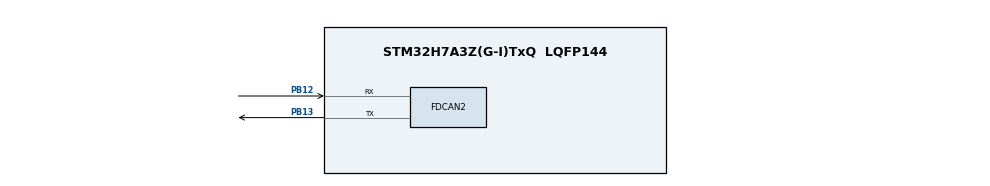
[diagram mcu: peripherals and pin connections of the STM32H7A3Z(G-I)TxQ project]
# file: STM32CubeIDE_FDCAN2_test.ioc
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FDCAN2.AutoRetransmission=ENABLE
FDCAN2.DataPrescaler=25
FDCAN2.DataTimeSeg1=2
FDCAN2.FrameFormat=FDCAN_FRAME_FD_NO_BRS
FDCAN2.MessageRAMOffset=11
FDCAN2.NominalSyncJumpWidth=13
FDCAN2.NominalTimeSeg1=86
FDCAN2.NominalTimeSeg2=13
FDCAN2.RxFifo1ElmtSize=FDCAN_DATA_BYTES_12
FDCAN2.RxFifo1ElmtsNbr=1
FDCAN2.TxElmtSize=FDCAN_DATA_BYTES_12
FDCAN2.TxFifoQueueElmtsNbr=1
Mcu.Family=STM32H7
Mcu.Name=STM32H7A3Z(G-I)TxQ
Mcu.Package=LQFP144
NVIC.FDCAN2_IT0_IRQn=true\:0\:0\:false\:false\:true\:true\:true
NVIC.PriorityGroup=NVIC_PRIORITYGROUP_4
PB12.Mode=FDCAN_Activate
PB12.Signal=FDCAN2_RX
PB13.Mode=FDCAN_Activate
PB13.Signal=FDCAN2_TX
ProjectManager.HeapSize=0x200
ProjectManager.StackSize=0x400
ProjectManager.TargetToolchain=STM32CubeIDE
RCC.ADCFreq_Value=129000000
RCC.APB1Freq_Value=32000000
RCC.APB2Freq_Value=32000000
RCC.APB3Freq_Value=32000000
RCC.APB4Freq_Value=32000000
RCC.CDPPRE=RCC_APB3_DIV2
RCC.CDPPRE1=RCC_APB1_DIV2
RCC.CDPPRE2=RCC_APB2_DIV2
RCC.CortexFreq_Value=64000000
RCC.DIVM1=4
RCC.DIVN1=8
RCC.DIVQ1=1
RCC.HCLKFreq_Value=64000000
RCC.PLLFRACN=0
RCC.SRDPPRE=RCC_APB4_DIV2
RCC.SYSCLKFreq_VALUE=64000000
RCC.USBFreq_Value=128000000
board=custom

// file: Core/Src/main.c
/* USER CODE BEGIN Header */
/**
  ******************************************************************************
  * @file           : main.c
  * @brief          : Main program body
  ******************************************************************************
  * @attention
  *
  * Copyright (c) 2023 STMicroelectronics.
  * All rights reserved.
  *
  * This software is licensed under terms that can be found in the LICENSE file
  * in the root directory of this software component.
  * If no LICENSE file comes with this software, it is provided AS-IS.
  *
  ******************************************************************************
  */
/* USER CODE END Header */
#include "main.h"

/* USER CODE BEGIN Includes */
#include <stdio.h>
/* USER CODE END Includes */

FDCAN_HandleTypeDef hfdcan2;

void SystemClock_Config(void);
static void MX_GPIO_Init(void);
static void MX_FDCAN2_Init(void);

/* USER CODE BEGIN 0 */

int indx = 0;
// FDCAN2 Defines
FDCAN_TxHeaderTypeDef   TxHeader2;
FDCAN_RxHeaderTypeDef   RxHeader2;
uint8_t               TxData2[12];
uint8_t               RxData2[12];

// FDCAN2 Callback
void HAL_FDCAN_RxFifo1Callback(FDCAN_HandleTypeDef *hfdcan, uint32_t RxFifo1ITs)
{
  if((RxFifo1ITs & FDCAN_IT_RX_FIFO1_NEW_MESSAGE) != RESET)
  {
    /* Retreive Rx messages from RX FIFO0 */
    if (HAL_FDCAN_GetRxMessage(hfdcan, FDCAN_RX_FIFO1, &RxHeader2, RxData2) != HAL_OK)
    {
    /* Reception Error */
    Error_Handler();
    }

    if (HAL_FDCAN_ActivateNotification(hfdcan, FDCAN_IT_RX_FIFO1_NEW_MESSAGE, 0) != HAL_OK)
    {
      /* Notification Error */
      Error_Handler();
    }

	  sprintf ((char *)TxData2, "FDCAN2TX %d", indx++);

	  if (HAL_FDCAN_AddMessageToTxFifoQ(&hfdcan2, &TxHeader2, TxData2)!= HAL_OK)
	  {
		  Error_Handler();
	  }
  }
}
/* USER CODE END 0 */

int main(void)
{

  /* MCU Configuration--------------------------------------------------------*/

  /* Reset of all peripherals, Initializes the Flash interface and the Systick. */
  HAL_Init();

  /* Configure the system clock */
  SystemClock_Config();

  /* Initialize all configured peripherals */
  MX_GPIO_Init();
  MX_FDCAN2_Init();
  /* USER CODE BEGIN 2 */

  // STart FDCAN2
   if(HAL_FDCAN_Start(&hfdcan2)!= HAL_OK)
   {
    Error_Handler();
   }
   // Activate the notification for new data in FIFO1 for FDCAN2
     if (HAL_FDCAN_ActivateNotification(&hfdcan2, FDCAN_IT_RX_FIFO1_NEW_MESSAGE, 0) != HAL_OK)
     {
       /* Notification Error */
       Error_Handler();
     }
     // Configure TX Header for FDCAN2
       TxHeader2.Identifier = 0x22;
       TxHeader2.IdType = FDCAN_STANDARD_ID;
       TxHeader2.TxFrameType = FDCAN_DATA_FRAME;
       TxHeader2.DataLength = FDCAN_DLC_BYTES_12;
       TxHeader2.ErrorStateIndicator = FDCAN_ESI_ACTIVE;
       TxHeader2.BitRateSwitch = FDCAN_BRS_OFF;
       TxHeader2.FDFormat = FDCAN_FD_CAN;
       TxHeader2.TxEventFifoControl = FDCAN_NO_TX_EVENTS;
       TxHeader2.MessageMarker = 0;

  /* USER CODE END 2 */

  /* Infinite loop */
  while (1)
  {

  }
}

void SystemClock_Config(void)
{
  RCC_OscInitTypeDef RCC_OscInitStruct = {0};
  RCC_ClkInitTypeDef RCC_ClkInitStruct = {0};

  /** Supply configuration update enable
  */
  HAL_PWREx_ConfigSupply(PWR_DIRECT_SMPS_SUPPLY);
  /** Configure the main internal regulator output voltage
  */
  __HAL_PWR_VOLTAGESCALING_CONFIG(PWR_REGULATOR_VOLTAGE_SCALE3);

  while(!__HAL_PWR_GET_FLAG(PWR_FLAG_VOSRDY)) {}
  /** Initializes the RCC Oscillators according to the specified parameters
  * in the RCC_OscInitTypeDef structure.
  */
  RCC_OscInitStruct.OscillatorType = RCC_OSCILLATORTYPE_HSI;
  RCC_OscInitStruct.HSIState = RCC_HSI_DIV1;
  RCC_OscInitStruct.HSICalibrationValue = RCC_HSICALIBRATION_DEFAULT;
  RCC_OscInitStruct.PLL.PLLState = RCC_PLL_ON;
  RCC_OscInitStruct.PLL.PLLSource = RCC_PLLSOURCE_HSI;
  RCC_OscInitStruct.PLL.PLLM = 4;
  RCC_OscInitStruct.PLL.PLLN = 8;
  RCC_OscInitStruct.PLL.PLLP = 2;
  RCC_OscInitStruct.PLL.PLLQ = 1;
  RCC_OscInitStruct.PLL.PLLR = 2;
  RCC_OscInitStruct.PLL.PLLRGE = RCC_PLL1VCIRANGE_3;
  RCC_OscInitStruct.PLL.PLLVCOSEL = RCC_PLL1VCOWIDE;
  RCC_OscInitStruct.PLL.PLLFRACN = 0;
  if (HAL_RCC_OscConfig(&RCC_OscInitStruct) != HAL_OK)
  {
    Error_Handler();
  }
  /** Initializes the CPU, AHB and APB buses clocks
  */
  RCC_ClkInitStruct.ClockType = RCC_CLOCKTYPE_HCLK|RCC_CLOCKTYPE_SYSCLK
                              |RCC_CLOCKTYPE_PCLK1|RCC_CLOCKTYPE_PCLK2
                              |RCC_CLOCKTYPE_D3PCLK1|RCC_CLOCKTYPE_D1PCLK1;
  RCC_ClkInitStruct.SYSCLKSource = RCC_SYSCLKSOURCE_HSI;
  RCC_ClkInitStruct.SYSCLKDivider = RCC_SYSCLK_DIV1;
  RCC_ClkInitStruct.AHBCLKDivider = RCC_HCLK_DIV1;
  RCC_ClkInitStruct.APB3CLKDivider = RCC_APB3_DIV2;
  RCC_ClkInitStruct.APB1CLKDivider = RCC_APB1_DIV2;
  RCC_ClkInitStruct.APB2CLKDivider = RCC_APB2_DIV2;
  RCC_ClkInitStruct.APB4CLKDivider = RCC_APB4_DIV2;

  if (HAL_RCC_ClockConfig(&RCC_ClkInitStruct, FLASH_LATENCY_2) != HAL_OK)
  {
    Error_Handler();
  }
}

static void MX_FDCAN2_Init(void)
{

  hfdcan2.Instance = FDCAN2;
  hfdcan2.Init.FrameFormat = FDCAN_FRAME_FD_NO_BRS;
  hfdcan2.Init.Mode = FDCAN_MODE_NORMAL;
  hfdcan2.Init.AutoRetransmission = ENABLE;
  hfdcan2.Init.TransmitPause = DISABLE;
  hfdcan2.Init.ProtocolException = DISABLE;
  hfdcan2.Init.NominalPrescaler = 1;
  hfdcan2.Init.NominalSyncJumpWidth = 13;
  hfdcan2.Init.NominalTimeSeg1 = 86;
  hfdcan2.Init.NominalTimeSeg2 = 13;
  hfdcan2.Init.DataPrescaler = 25;
  hfdcan2.Init.DataSyncJumpWidth = 1;
  hfdcan2.Init.DataTimeSeg1 = 2;
  hfdcan2.Init.DataTimeSeg2 = 1;
  hfdcan2.Init.MessageRAMOffset = 11;
  hfdcan2.Init.StdFiltersNbr = 0;
  hfdcan2.Init.ExtFiltersNbr = 0;
  hfdcan2.Init.RxFifo0ElmtsNbr = 0;
  hfdcan2.Init.RxFifo0ElmtSize = FDCAN_DATA_BYTES_8;
  hfdcan2.Init.RxFifo1ElmtsNbr = 1;
  hfdcan2.Init.RxFifo1ElmtSize = FDCAN_DATA_BYTES_12;
  hfdcan2.Init.RxBuffersNbr = 0;
  hfdcan2.Init.RxBufferSize = FDCAN_DATA_BYTES_8;
  hfdcan2.Init.TxEventsNbr = 0;
  hfdcan2.Init.TxBuffersNbr = 0;
  hfdcan2.Init.TxFifoQueueElmtsNbr = 1;
  hfdcan2.Init.TxFifoQueueMode = FDCAN_TX_FIFO_OPERATION;
  hfdcan2.Init.TxElmtSize = FDCAN_DATA_BYTES_12;
  if (HAL_FDCAN_Init(&hfdcan2) != HAL_OK)
  {
    Error_Handler();
  }
  /* USER CODE BEGIN FDCAN2_Init 2 */

  FDCAN_FilterTypeDef sFilterConfig;

    sFilterConfig.IdType = FDCAN_STANDARD_ID;
    sFilterConfig.FilterIndex = 0;
    sFilterConfig.FilterType = FDCAN_FILTER_MASK;
    sFilterConfig.FilterConfig = FDCAN_FILTER_TO_RXFIFO1;
    sFilterConfig.FilterID1 = 0x11;
    sFilterConfig.FilterID2 = 0x11;
    sFilterConfig.RxBufferIndex = 0;
    if (HAL_FDCAN_ConfigFilter(&hfdcan2, &sFilterConfig) != HAL_OK)
    {
      /* Filter configuration Error */
      Error_Handler();
    }

  /* USER CODE END FDCAN2_Init 2 */

}

static void MX_GPIO_Init(void)
{

  /* GPIO Ports Clock Enable */
  __HAL_RCC_GPIOB_CLK_ENABLE();

}

void Error_Handler(void)
{
  __disable_irq();
  while (1)
  {
  }
}
